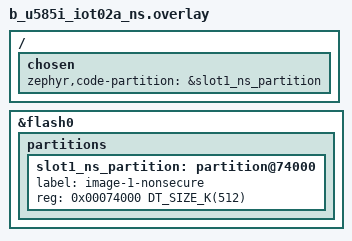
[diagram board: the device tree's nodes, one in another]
/*
 * Copyright (c) 2022, STMicroelectronics
 *
 * SPDX-License-Identifier: Apache-2.0
 */
 /{
	chosen {
		zephyr,code-partition = &slot1_ns_partition;
	};
};

&flash0 {
	partitions {
	/delete-node/ slot1_partition;
		/* Non-secure image primary slot */
		slot1_ns_partition: partition@74000 {
			label = "image-1-nonsecure";
			reg = <0x00074000 DT_SIZE_K(512)>;
		};
	};
};
